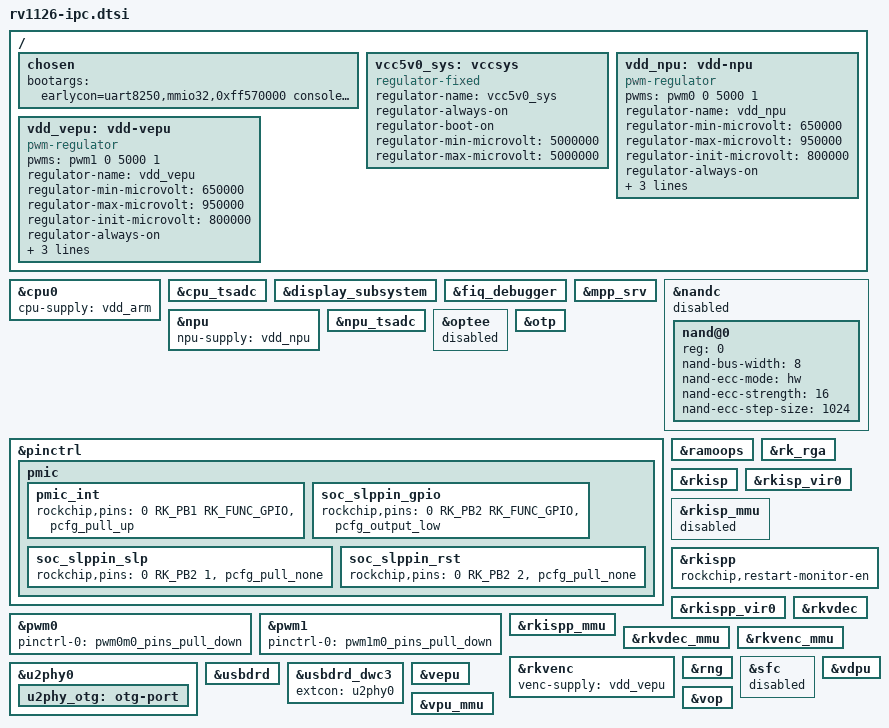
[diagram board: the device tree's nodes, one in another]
// SPDX-License-Identifier: (GPL-2.0+ OR MIT)
/*
 * Copyright (c) 2020 Fuzhou Rockchip Electronics Co., Ltd.
 */

/ {
	chosen {
		bootargs = "earlycon=uart8250,mmio32,0xff570000 console=ttyFIQ0 root=PARTUUID=614e0000-0000 rootfstype=ext4 rootwait snd_aloop.index=7";
	};

	vcc5v0_sys: vccsys {
		compatible = "regulator-fixed";
		regulator-name = "vcc5v0_sys";
		regulator-always-on;
		regulator-boot-on;
		regulator-min-microvolt = <5000000>;
		regulator-max-microvolt = <5000000>;
	};

	vdd_npu: vdd-npu {
		compatible = "pwm-regulator";
		pwms = <&pwm0 0 5000 1>;
		regulator-name = "vdd_npu";
		regulator-min-microvolt = <650000>;
		regulator-max-microvolt = <950000>;
		regulator-init-microvolt = <800000>;
		regulator-always-on;
		regulator-boot-on;
		regulator-settling-time-up-us = <250>;
		pwm-supply = <&vcc5v0_sys>;
		status = "okay";
	};

	vdd_vepu: vdd-vepu {
		compatible = "pwm-regulator";
		pwms = <&pwm1 0 5000 1>;
		regulator-name = "vdd_vepu";
		regulator-min-microvolt = <650000>;
		regulator-max-microvolt = <950000>;
		regulator-init-microvolt = <800000>;
		regulator-always-on;
		regulator-boot-on;
		regulator-settling-time-up-us = <250>;
		pwm-supply = <&vcc5v0_sys>;
		status = "okay";
	};
};

&cpu0 {
	cpu-supply = <&vdd_arm>;
};

&cpu_tsadc {
	status = "okay";
};

&display_subsystem {
	status = "okay";
};

&fiq_debugger {
	status = "okay";
};

&mpp_srv {
	status = "okay";
};

&nandc {
	/delete-property/ pinctrl-names;
	/delete-property/ pinctrl-0;
	status = "disabled";
	#address-cells = <1>;
	#size-cells = <0>;

	nand@0 {
		reg = <0>;
		nand-bus-width = <8>;
		nand-ecc-mode = "hw";
		nand-ecc-strength = <16>;
		nand-ecc-step-size = <1024>;
	};
};

&npu {
	npu-supply = <&vdd_npu>;
	status = "okay";
};

&npu_tsadc {
	status = "okay";
};

&optee {
	status = "disabled";
};

&otp {
	status = "okay";
};

&pinctrl {
	pmic {
		/omit-if-no-ref/
		pmic_int: pmic_int {
			rockchip,pins =
				<0 RK_PB1 RK_FUNC_GPIO &pcfg_pull_up>;
		};

		/omit-if-no-ref/
		soc_slppin_gpio: soc_slppin_gpio {
			rockchip,pins =
				<0 RK_PB2 RK_FUNC_GPIO &pcfg_output_low>;
		};

		/omit-if-no-ref/
		soc_slppin_slp: soc_slppin_slp {
			rockchip,pins =
				<0 RK_PB2 1 &pcfg_pull_none>;
		};

		/omit-if-no-ref/
		soc_slppin_rst: soc_slppin_rst {
			rockchip,pins =
				<0 RK_PB2 2 &pcfg_pull_none>;
		};
	};
};

&pwm0 {
	status = "okay";
	pinctrl-names = "active";
	pinctrl-0 = <&pwm0m0_pins_pull_down>;
};

&pwm1 {
	status = "okay";
	pinctrl-names = "active";
	pinctrl-0 = <&pwm1m0_pins_pull_down>;
};

&ramoops {
	status = "okay";
};

&rk_rga {
	status = "okay";
};

&rkisp {
	status = "okay";
};

&rkisp_vir0 {
	status = "okay";
};

&rkisp_mmu {
	status = "disabled";
};

&rkispp {
	rockchip,restart-monitor-en;
	status = "okay";
};

&rkispp_vir0 {
	status = "okay";
};

&rkispp_mmu {
	status = "okay";
};

&rkvdec {
	status = "okay";
};

&rkvdec_mmu {
	status = "okay";
};

&rkvenc {
	venc-supply = <&vdd_vepu>;
	status = "okay";
};

&rkvenc_mmu {
	status = "okay";
};

&rng {
	status = "okay";
};

&sfc {
	/delete-property/ pinctrl-names;
	/delete-property/ pinctrl-0;
	status = "disabled";
};

&u2phy0 {
	status = "okay";
	u2phy_otg: otg-port {
		status = "okay";
	};
};

&usbdrd {
	status = "okay";
};

&usbdrd_dwc3 {
	status = "okay";
	extcon = <&u2phy0>;
};

&vdpu {
	status = "okay";
};

&vepu {
	status = "okay";
};

&vpu_mmu {
	status = "okay";
};

&vop {
	status = "okay";
};
